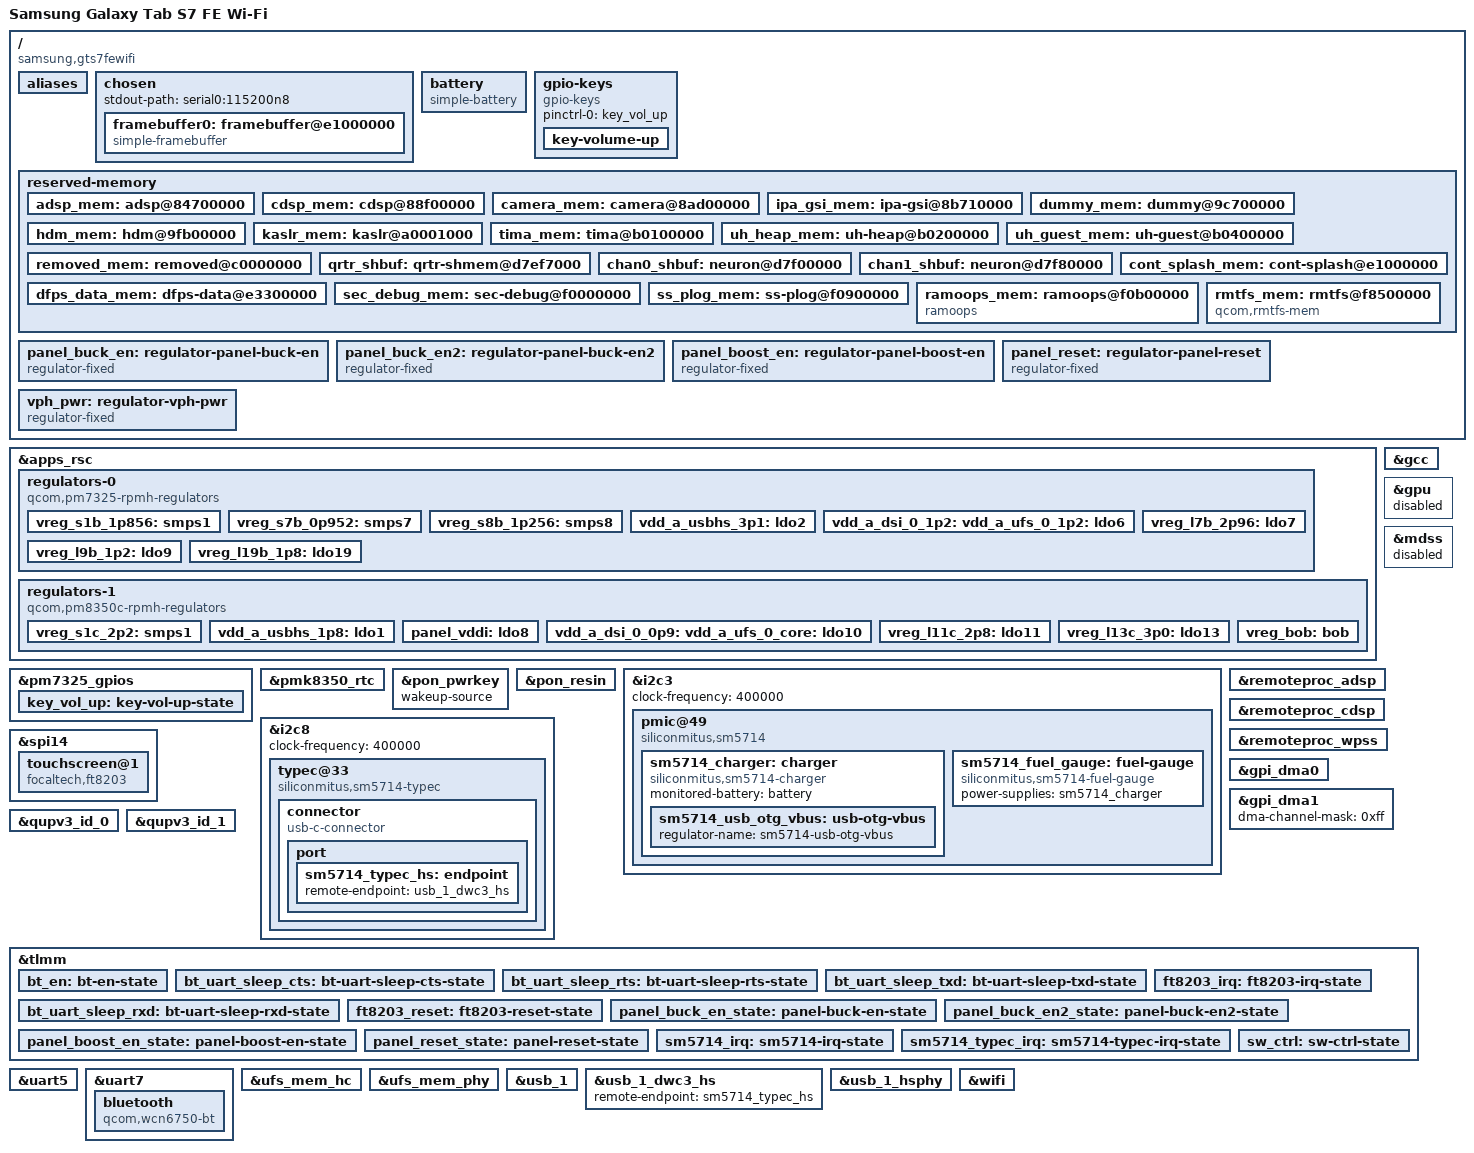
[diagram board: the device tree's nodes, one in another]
// SPDX-License-Identifier: (GPL-2.0+ OR BSD-3-Clause)
/*
 * Copyright (c) 2026 XiaoYeZi
 */

/dts-v1/;

#include <dt-bindings/gpio/gpio.h>
#include <dt-bindings/input/input.h>
#include <dt-bindings/interrupt-controller/irq.h>
#include <dt-bindings/pinctrl/qcom,pmic-gpio.h>
#include <dt-bindings/regulator/qcom,rpmh-regulator.h>

#include "sm7325.dtsi"
#include "pm7325.dtsi"
#include "pm8350c.dtsi" /* PM7350C */
#include "pmk8350.dtsi" /* PMK7325 */

/delete-node/ &adsp_mem;
/delete-node/ &cdsp_mem;
/delete-node/ &rmtfs_mem;

/ {
	model = "Samsung Galaxy Tab S7 FE Wi-Fi";
	compatible = "samsung,gts7fewifi", "qcom,sm7325";
	chassis-type = "tablet";

	aliases {
		bluetooth0 = &bluetooth;
		serial0 = &uart5;
		serial1 = &uart7;
		wifi0 = &wifi;
	};

	chosen {
		#address-cells = <2>;
		#size-cells = <2>;
		ranges;

		stdout-path = "serial0:115200n8";

		framebuffer0: framebuffer@e1000000 {
			compatible = "simple-framebuffer";
			reg = <0x0 0xe1000000 0x0 0x02300000>;
			width = <1600>;
			height = <2560>;
			stride = <(1600 * 4)>;
			format = "a8r8g8b8";

			clocks = <&gcc GCC_DISP_HF_AXI_CLK>,
				 <&dispcc DISP_CC_MDSS_MDP_CLK>,
				 <&dispcc DISP_CC_MDSS_BYTE0_CLK>,
				 <&dispcc DISP_CC_MDSS_BYTE0_INTF_CLK>,
				 <&dispcc DISP_CC_MDSS_PCLK0_CLK>,
				 <&dispcc DISP_CC_MDSS_VSYNC_CLK>;
			power-domains = <&dispcc DISP_CC_MDSS_CORE_GDSC>;
		};
	};

	battery: battery {
		compatible = "simple-battery";
		charge-full-design-microamp-hours = <10090000>;
		constant-charge-voltage-max-microvolt = <4380000>;
		voltage-max-design-microvolt = <4380000>;
		voltage-min-design-microvolt = <3200000>;
	};

	gpio-keys {
		compatible = "gpio-keys";

		pinctrl-0 = <&key_vol_up>;
		pinctrl-names = "default";

		key-volume-up {
			label = "Volume Up";
			gpios = <&pm7325_gpios 6 GPIO_ACTIVE_LOW>;
			linux,code = <KEY_VOLUMEUP>;
			wakeup-source;
		};
	};

	reserved-memory {
		#address-cells = <2>;
		#size-cells = <2>;
		ranges;

		adsp_mem: adsp@84700000 {
			reg = <0x0 0x84700000 0x0 0x4800000>;
			no-map;
		};

		cdsp_mem: cdsp@88f00000 {
			reg = <0x0 0x88f00000 0x0 0x1e00000>;
			no-map;
		};

		camera_mem: camera@8ad00000 {
			reg = <0x0 0x8ad00000 0x0 0x500000>;
			no-map;
		};

		ipa_gsi_mem: ipa-gsi@8b710000 {
			reg = <0x0 0x8b710000 0x0 0xa000>;
			no-map;
		};

		dummy_mem: dummy@9c700000 {
			reg = <0x0 0x9c700000 0x0 0x100000>;
			no-map;
		};

		hdm_mem: hdm@9fb00000 {
			reg = <0x0 0x9fb00000 0x0 0x1000>;
			no-map;
		};

		kaslr_mem: kaslr@a0001000 {
			reg = <0x0 0xa0001000 0x0 0x1000>;
			no-map;
		};

		tima_mem: tima@b0100000 {
			reg = <0x0 0xb0100000 0x0 0x100000>;
			no-map;
		};

		uh_heap_mem: uh-heap@b0200000 {
			reg = <0x0 0xb0200000 0x0 0x200000>;
			no-map;
		};

		uh_guest_mem: uh-guest@b0400000 {
			reg = <0x0 0xb0400000 0x0 0xe00000>;
			no-map;
		};

		removed_mem: removed@c0000000 {
			reg = <0x0 0xc0000000 0x0 0x5f00000>;
			no-map;
		};

		qrtr_shbuf: qrtr-shmem@d7ef7000 {
			reg = <0x0 0xd7ef7000 0x0 0x9000>;
			no-map;
		};

		chan0_shbuf: neuron@d7f00000 {
			reg = <0x0 0xd7f00000 0x0 0x80000>;
			no-map;
		};

		chan1_shbuf: neuron@d7f80000 {
			reg = <0x0 0xd7f80000 0x0 0x80000>;
			no-map;
		};

		cont_splash_mem: cont-splash@e1000000 {
			reg = <0x0 0xe1000000 0x0 0x02300000>;
			no-map;
		};

		dfps_data_mem: dfps-data@e3300000 {
			reg = <0x0 0xe3300000 0x0 0x100000>;
			no-map;
		};

		sec_debug_mem: sec-debug@f0000000 {
			reg = <0x0 0xf0000000 0x0 0x900000>;
			no-map;
		};

		ss_plog_mem: ss-plog@f0900000 {
			reg = <0x0 0xf0900000 0x0 0x200000>;
			no-map;
		};

		ramoops_mem: ramoops@f0b00000 {
			compatible = "ramoops";
			reg = <0x0 0xf0b00000 0x0 0x100000>;
			record-size = <0x40000>;
			console-size = <0x40000>;
			ftrace-size = <0x40000>;
			pmsg-size = <0x40000>;
		};

		rmtfs_mem: rmtfs@f8500000 {
			compatible = "qcom,rmtfs-mem";
			reg = <0x0 0xf8500000 0x0 0x600000>;
			no-map;

			qcom,client-id = <1>;
			qcom,vmid = <QCOM_SCM_VMID_MSS_MSA>,
				    <QCOM_SCM_VMID_NAV>;
		};
	};

	panel_buck_en: regulator-panel-buck-en {
		compatible = "regulator-fixed";
		regulator-name = "panel_buck_en";
		gpio = <&tlmm 96 GPIO_ACTIVE_HIGH>;
		enable-active-high;
		regulator-always-on;
		regulator-boot-on;
		pinctrl-0 = <&panel_buck_en_state>;
		pinctrl-names = "default";
	};

	panel_buck_en2: regulator-panel-buck-en2 {
		compatible = "regulator-fixed";
		regulator-name = "panel_buck_en2";
		gpio = <&tlmm 97 GPIO_ACTIVE_HIGH>;
		enable-active-high;
		regulator-always-on;
		regulator-boot-on;
		pinctrl-0 = <&panel_buck_en2_state>;
		pinctrl-names = "default";
	};

	panel_boost_en: regulator-panel-boost-en {
		compatible = "regulator-fixed";
		regulator-name = "panel_boost_en";
		gpio = <&tlmm 98 GPIO_ACTIVE_HIGH>;
		enable-active-high;
		regulator-always-on;
		regulator-boot-on;
		pinctrl-0 = <&panel_boost_en_state>;
		pinctrl-names = "default";
	};

	panel_reset: regulator-panel-reset {
		compatible = "regulator-fixed";
		regulator-name = "panel_reset";
		gpio = <&tlmm 44 GPIO_ACTIVE_HIGH>;
		enable-active-high;
		regulator-always-on;
		regulator-boot-on;
		pinctrl-0 = <&panel_reset_state>;
		pinctrl-names = "default";
	};

	vph_pwr: regulator-vph-pwr {
		compatible = "regulator-fixed";
		regulator-name = "vph_pwr";
		regulator-min-microvolt = <3700000>;
		regulator-max-microvolt = <3700000>;
	};
};

&apps_rsc {
	regulators-0 {
		compatible = "qcom,pm7325-rpmh-regulators";
		qcom,pmic-id = "b";

		vdd-s1-supply = <&vph_pwr>;
		vdd-s7-supply = <&vph_pwr>;
		vdd-s8-supply = <&vph_pwr>;

		vdd-l2-l7-supply = <&vreg_bob>;
		vdd-l6-l9-l10-supply = <&vreg_s8b_1p256>;
		vdd-l11-l17-l18-l19-supply = <&vreg_s1b_1p856>;

		vreg_s1b_1p856: smps1 {
			regulator-name = "vreg_s1b_1p856";
			regulator-min-microvolt = <1840000>;
			regulator-max-microvolt = <2040000>;
		};

		vreg_s7b_0p952: smps7 {
			regulator-name = "vreg_s7b_0p952";
			regulator-min-microvolt = <535000>;
			regulator-max-microvolt = <1120000>;
		};

		vreg_s8b_1p256: smps8 {
			regulator-name = "vreg_s8b_1p256";
			regulator-min-microvolt = <1200000>;
			regulator-max-microvolt = <1500000>;
			regulator-initial-mode = <RPMH_REGULATOR_MODE_RET>;
		};

		vdd_a_usbhs_3p1: ldo2 {
			regulator-name = "vreg_l2b_3p072";
			regulator-min-microvolt = <2700000>;
			regulator-max-microvolt = <3544000>;
			regulator-initial-mode = <RPMH_REGULATOR_MODE_HPM>;
		};

		vdd_a_dsi_0_1p2:
		vdd_a_ufs_0_1p2: ldo6 {
			regulator-name = "vreg_l6b_1p2";
			regulator-min-microvolt = <1140000>;
			regulator-max-microvolt = <1260000>;
			regulator-initial-mode = <RPMH_REGULATOR_MODE_HPM>;
		};

		vreg_l7b_2p96: ldo7 {
			regulator-name = "vreg_l7b_2p96";
			regulator-min-microvolt = <2400000>;
			regulator-max-microvolt = <3544000>;
			regulator-initial-mode = <RPMH_REGULATOR_MODE_HPM>;
		};

		vreg_l9b_1p2: ldo9 {
			regulator-name = "vreg_l9b_1p2";
			regulator-min-microvolt = <1200000>;
			regulator-max-microvolt = <1304000>;
			regulator-initial-mode = <RPMH_REGULATOR_MODE_HPM>;
		};

		vreg_l19b_1p8: ldo19 {
			regulator-name = "vreg_l19b_1p8";
			regulator-min-microvolt = <1800000>;
			regulator-max-microvolt = <2000000>;
			regulator-initial-mode = <RPMH_REGULATOR_MODE_HPM>;
		};
	};

	regulators-1 {
		compatible = "qcom,pm8350c-rpmh-regulators";
		qcom,pmic-id = "c";

		vdd-s1-supply = <&vph_pwr>;
		vdd-bob-supply = <&vph_pwr>;
		vdd-l1-l12-supply = <&vreg_s1b_1p856>;
		vdd-l2-l8-supply = <&vreg_s1b_1p856>;
		vdd-l3-l4-l5-l7-l13-supply = <&vreg_bob>;
		vdd-l6-l9-l11-supply = <&vreg_bob>;
		vdd-l10-supply = <&vreg_s7b_0p952>;

		vreg_s1c_2p2: smps1 {
			regulator-name = "vreg_s1c_2p2";
			regulator-min-microvolt = <2190000>;
			regulator-max-microvolt = <2210000>;
		};

		vdd_a_usbhs_1p8: ldo1 {
			regulator-name = "vreg_l1c_1p8";
			regulator-min-microvolt = <1800000>;
			regulator-max-microvolt = <1980000>;
			regulator-initial-mode = <RPMH_REGULATOR_MODE_HPM>;
		};

		panel_vddi: ldo8 {
			regulator-name = "panel_vddi";
			regulator-enable-ramp-delay = <3000>;
			regulator-min-microvolt = <1904000>;
			regulator-max-microvolt = <1904000>;
			regulator-initial-mode = <RPMH_REGULATOR_MODE_HPM>;
			regulator-always-on;
			regulator-boot-on;
		};

		vdd_a_dsi_0_0p9:
		vdd_a_ufs_0_core:
		vdd_a_usbhs_core: ldo10 {
			regulator-name = "vreg_l10c_0p88";
			regulator-min-microvolt = <720000>;
			regulator-max-microvolt = <1050000>;
			regulator-initial-mode = <RPMH_REGULATOR_MODE_HPM>;
		};

		vreg_l11c_2p8: ldo11 {
			regulator-name = "vreg_l11c_2p8";
			regulator-min-microvolt = <2800000>;
			regulator-max-microvolt = <3544000>;
			regulator-initial-mode = <RPMH_REGULATOR_MODE_HPM>;
		};

		vreg_l13c_3p0: ldo13 {
			regulator-name = "vreg_l13c_3p0";
			regulator-min-microvolt = <2700000>;
			regulator-max-microvolt = <3544000>;
			regulator-initial-mode = <RPMH_REGULATOR_MODE_HPM>;
			regulator-boot-on;
		};

		vreg_bob: bob {
			regulator-name = "vreg_bob";
			regulator-min-microvolt = <3008000>;
			regulator-max-microvolt = <3960000>;
			regulator-initial-mode = <RPMH_REGULATOR_MODE_AUTO>;
		};
	};
};

&gcc {
	protected-clocks = <GCC_CFG_NOC_LPASS_CLK>,
			   <GCC_MSS_CFG_AHB_CLK>,
			   <GCC_MSS_OFFLINE_AXI_CLK>,
			   <GCC_MSS_Q6SS_BOOT_CLK_SRC>,
			   <GCC_MSS_Q6_MEMNOC_AXI_CLK>,
			   <GCC_MSS_SNOC_AXI_CLK>,
			   <GCC_QSPI_CNOC_PERIPH_AHB_CLK>,
			   <GCC_QSPI_CORE_CLK>,
			   <GCC_QSPI_CORE_CLK_SRC>,
			   <GCC_SEC_CTRL_CLK_SRC>,
			   <GCC_WPSS_AHB_BDG_MST_CLK>,
			   <GCC_WPSS_AHB_CLK>,
			   <GCC_WPSS_RSCP_CLK>;
};
/*
&i2c10 {
	clock-frequency = <400000>;
	status = "disabled";

	regulator@18 {
		compatible = "maxim,max77816";
		reg = <0x18>;

		enable-gpios = <&tlmm 98 GPIO_ACTIVE_HIGH>;
		regulator-enable-ramp-delay = <1000>;
		regulator-max-microvolt = <5000000>;
		regulator-min-microvolt = <5000000>;
		regulator-name = "panel_backlight_boost";
	};

	regulator@29 {
		compatible = "renesas,isl98608";
		reg = <0x29>;
		vin-supply = <&panel_vddi>;

		regulators {
			panel_avdd: avdd {
				enable-gpios = <&tlmm 96 GPIO_ACTIVE_HIGH>;
				regulator-enable-ramp-delay = <4000>;
				regulator-max-microvolt = <5600000>;
				regulator-min-microvolt = <5600000>;
				regulator-name = "panel_avdd";
			};

			panel_avee: avee {
				enable-gpios = <&tlmm 97 GPIO_ACTIVE_HIGH>;
				regulator-enable-ramp-delay = <3000>;
				regulator-max-microvolt = <5600000>;
				regulator-min-microvolt = <5600000>;
				regulator-name = "panel_avee";
			};
		};
	};
};
*/
&pm7325_gpios {
	key_vol_up: key-vol-up-state {
		pins = "gpio6";
		function = "normal";
		input-enable;
		bias-pull-up;
		power-source = <1>;
	};
};

&pmk8350_rtc {
	status = "okay";
};

&pon_pwrkey {
	status = "okay";
	wakeup-source;
};

&pon_resin {
	linux,code = <KEY_VOLUMEDOWN>;
	status = "okay";
	wakeup-source;
};

&gpu {
	status = "disabled";
};

&i2c3 {
	clock-frequency = <400000>;
	status = "okay";

	pmic@49 {
		compatible = "siliconmitus,sm5714";
		reg = <0x49>;

		interrupt-parent = <&tlmm>;
		interrupts = <54 IRQ_TYPE_LEVEL_LOW>;
		pinctrl-0 = <&sm5714_irq>;
		pinctrl-names = "default";
		wakeup-source;

		sm5714_charger: charger {
			compatible = "siliconmitus,sm5714-charger";
			monitored-battery = <&battery>;

			sm5714_usb_otg_vbus: usb-otg-vbus {
				regulator-name = "sm5714-usb-otg-vbus";
			};
		};

		sm5714_fuel_gauge: fuel-gauge {
			compatible = "siliconmitus,sm5714-fuel-gauge";
			power-supplies = <&sm5714_charger>;
		};
	};
};

&i2c8 {
	clock-frequency = <400000>;
	status = "okay";

	typec@33 {
		compatible = "siliconmitus,sm5714-typec";
		reg = <0x33>;

		interrupt-parent = <&tlmm>;
		interrupts = <142 IRQ_TYPE_LEVEL_LOW>;
		pinctrl-0 = <&sm5714_typec_irq>;
		pinctrl-names = "default";
		vbus-supply = <&sm5714_usb_otg_vbus>;
		wakeup-source;

		connector {
			compatible = "usb-c-connector";
			data-role = "dual";
			power-role = "dual";
			try-power-role = "sink";
			typec-power-opmode = "default";

			port {
				sm5714_typec_hs: endpoint {
					remote-endpoint = <&usb_1_dwc3_hs>;
				};
			};
		};
	};
};

&mdss {
	status = "disabled";
};

/*
&mdss_dsi {
	vdda-supply = <&vdd_a_dsi_0_1p2>;
	status = "disabled";

	panel: panel@0 {
		compatible = "boe,ts124qdm";
		reg = <0>;

		avdd-supply = <&panel_avdd>;
		avee-supply = <&panel_avee>;
		power-supply = <&panel_power>;
		vddi-supply = <&panel_vddi>;

		port {
			panel_in: endpoint {
				remote-endpoint = <&mdss_dsi0_out>;
			};
		};
	};
};

&mdss_dsi0_out {
	data-lanes = <0 1 2 3>;
	remote-endpoint = <&panel_in>;
};

&mdss_dsi_phy {
	vdds-supply = <&vdd_a_dsi_0_0p9>;
	status = "disabled";
};
*/
&remoteproc_adsp {
	firmware-name = "qcom/sm7325/samsung/gts7fewifi/adsp.mbn";
	status = "okay";
};

&remoteproc_cdsp {
	firmware-name = "qcom/sm7325/samsung/gts7fewifi/cdsp.mbn";
	status = "okay";
};

&remoteproc_wpss {
	firmware-name = "qcom/sm7325/samsung/gts7fewifi/wpss.mbn";
	status = "okay";
};

&spi14 {
	cs-gpios = <0>, <&tlmm 59 GPIO_ACTIVE_LOW>;
	pinctrl-0 = <&qup_spi14_data_clk>, <&qup_spi14_cs_gpio>;
	pinctrl-names = "default";
	status = "okay";

	touchscreen@1 {
		compatible = "focaltech,ft8203";
		reg = <1>;
		spi-max-frequency = <6000000>;

		interrupt-parent = <&tlmm>;
		interrupts = <81 IRQ_TYPE_EDGE_FALLING>;
		reset-gpios = <&tlmm 50 GPIO_ACTIVE_LOW>;
		firmware-name = "focaltech/ft8203_gts7xllite.bin";
		pinctrl-0 = <&ft8203_irq>, <&ft8203_reset>;
		pinctrl-names = "default";

		touchscreen-size-x = <1600>;
		touchscreen-size-y = <2560>;
	};
};

&gpi_dma0 {
	status = "okay";
};

&gpi_dma1 {
	/*
	 * SM7325 has all 8 GPII instances of the second GPI DMA controller
	 * wired to QUP1 serial engines.  The default 0x1e mask only covers
	 * SE9-SE12 and would prevent the USB-C controller (I2C8) from
	 * getting DMA channels, matching the downstream Samsung
	 * configuration.
	 */
	dma-channel-mask = <0xff>;
	status = "okay";
};

&qupv3_id_0 {
	status = "okay";
};

&qupv3_id_1 {
	status = "okay";
};
&tlmm {
	bt_en: bt-en-state {
		pins = "gpio85";
		function = "gpio";
		output-low;
		bias-disable;
	};

	bt_uart_sleep_cts: bt-uart-sleep-cts-state {
		pins = "gpio28";
		function = "gpio";
		bias-bus-hold;
	};

	bt_uart_sleep_rts: bt-uart-sleep-rts-state {
		pins = "gpio29";
		function = "gpio";
		bias-pull-down;
	};

	bt_uart_sleep_txd: bt-uart-sleep-txd-state {
		pins = "gpio30";
		function = "gpio";
		bias-pull-up;
	};

	bt_uart_sleep_rxd: bt-uart-sleep-rxd-state {
		pins = "gpio31";
		function = "gpio";
		bias-pull-up;
	};

	ft8203_irq: ft8203-irq-state {
		pins = "gpio81";
		function = "gpio";
		input-enable;
		bias-pull-up;
	};

	ft8203_reset: ft8203-reset-state {
		pins = "gpio50";
		function = "gpio";
		bias-disable;
	};

	panel_buck_en_state: panel-buck-en-state {
		pins = "gpio96";
		function = "gpio";
		output-high;
		bias-disable;
	};

	panel_buck_en2_state: panel-buck-en2-state {
		pins = "gpio97";
		function = "gpio";
		output-high;
		bias-disable;
	};

	panel_boost_en_state: panel-boost-en-state {
		pins = "gpio98";
		function = "gpio";
		output-high;
		bias-disable;
	};

	panel_reset_state: panel-reset-state {
		pins = "gpio44";
		function = "gpio";
		output-high;
		bias-disable;
	};

	sm5714_irq: sm5714-irq-state {
		pins = "gpio54";
		function = "gpio";
		input-enable;
		bias-disable;
	};

	sm5714_typec_irq: sm5714-typec-irq-state {
		pins = "gpio142";
		function = "gpio";
		drive-strength = <8>;
		input-enable;
		bias-disable;
	};

	sw_ctrl: sw-ctrl-state {
		pins = "gpio86";
		function = "gpio";
		input-enable;
		bias-pull-down;
	};

};

&uart5 {
	status = "okay";
};

&uart7 {
	/delete-property/ interrupts;
	interrupts-extended = <&intc GIC_SPI 608 IRQ_TYPE_LEVEL_HIGH>,
			      <&tlmm 31 IRQ_TYPE_EDGE_FALLING>;
	pinctrl-1 = <&bt_uart_sleep_cts>,
		    <&bt_uart_sleep_rts>,
		    <&bt_uart_sleep_txd>,
		    <&bt_uart_sleep_rxd>;
	pinctrl-names = "default", "sleep";

	status = "okay";

	bluetooth: bluetooth {
		compatible = "qcom,wcn6750-bt";
		pinctrl-0 = <&bt_en>, <&sw_ctrl>;
		pinctrl-names = "default";
		enable-gpios = <&tlmm 85 GPIO_ACTIVE_HIGH>;
		swctrl-gpios = <&tlmm 86 GPIO_ACTIVE_HIGH>;
		vddio-supply = <&vreg_l19b_1p8>;
		vddaon-supply = <&vreg_s7b_0p952>;
		vddbtcxmx-supply = <&vreg_s7b_0p952>;
		vddrfacmn-supply = <&vreg_s7b_0p952>;
		vddrfa0p8-supply = <&vreg_s7b_0p952>;
		vddrfa1p7-supply = <&vreg_s1b_1p856>;
		vddrfa1p2-supply = <&vreg_s8b_1p256>;
		vddrfa2p2-supply = <&vreg_s1c_2p2>;
		vddasd-supply = <&vreg_l11c_2p8>;
		max-speed = <3200000>;

		qcom,local-bd-address-broken;
	};
};

&ufs_mem_hc {
	reset-gpios = <&tlmm 175 GPIO_ACTIVE_LOW>;

	vcc-supply = <&vreg_l7b_2p96>;
	vcc-max-microamp = <800000>;
	vccq-supply = <&vreg_l9b_1p2>;
	vccq-max-microamp = <900000>;

	status = "okay";
};

&ufs_mem_phy {
	vdda-phy-supply = <&vdd_a_ufs_0_core>;
	vdda-pll-supply = <&vdd_a_ufs_0_1p2>;
	status = "okay";
};

&usb_1 {
	qcom,select-utmi-as-pipe-clk;
	dr_mode = "otg";
	usb-role-switch;
	maximum-speed = "high-speed";
	phys = <&usb_1_hsphy>;
	phy-names = "usb2-phy";
	status = "okay";
};

&usb_1_dwc3_hs {
	remote-endpoint = <&sm5714_typec_hs>;
};

&usb_1_hsphy {
	vdda-pll-supply = <&vdd_a_usbhs_core>;
	vdda18-supply = <&vdd_a_usbhs_1p8>;
	vdda33-supply = <&vdd_a_usbhs_3p1>;
	status = "okay";
};

&wifi {
	status = "okay";
};
